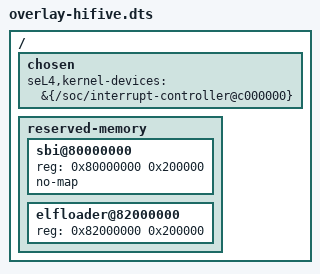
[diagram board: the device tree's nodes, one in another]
/*
 * Copyright 2020, Data61, CSIRO (ABN 41 687 119 230)
 * Copyright 2021, HENSOLDT Cyber
 *
 * SPDX-License-Identifier: GPL-2.0-only
 */

/ {
	chosen {
		seL4,kernel-devices =
		    &{/soc/interrupt-controller@c000000};
	};

    reserved-memory {
        #address-cells = <0x01>;
        #size-cells = <0x01>;
        ranges;

        /* Reserve 2 MiB for SBI at the start of RAM (0x80000000 - 0x80200000).
         * This is exactly one "megapage" in the MMU table. It leaves plenty of
         * space for further SBI experimenting, given the known usage (as of
         * June 2021) is:
         * - BBL: 76 KiB (= 0x13000)
         * - OpenSBI: 128 KiB (= 0x20000) with PMP protection
         */
        sbi@80000000 {
            reg = <0x80000000 0x200000>;
            no-map;
        };

        /* Reserve 2 MiB for the Elfloader after SBI (0x82000000 - 0x84000000).
         * Since "no-map" is not given, this memory can be re-used by the kernel
         * once control has been handed over
         */
        elfloader@82000000 {
            device_type = "elfloader";
            reg = <0x82000000 0x200000>;
        };

    };

};
